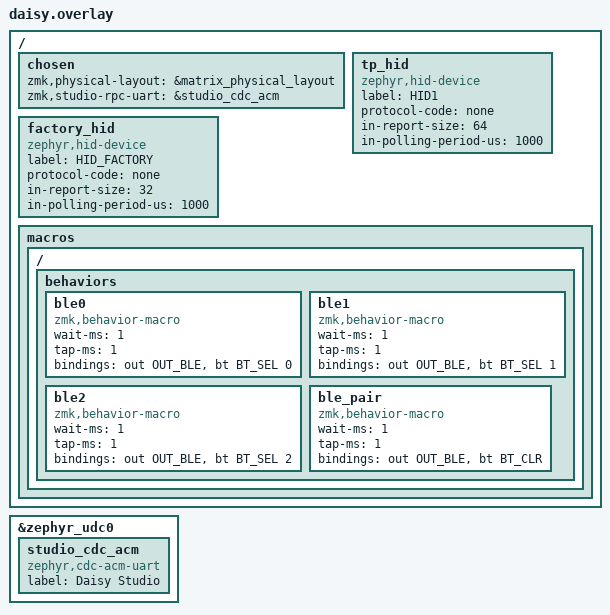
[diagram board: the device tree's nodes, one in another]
/*
 * Copyright (c) 2022 The ZMK Contributors
 *
 * SPDX-License-Identifier: MIT
 */

/* Keep every behavior node, not just the ones the keymap references, so
 * ZMK Studio can assign them at runtime (what the upstream
 * studio-rpc-usb-uart snippet does via DTS_EXTRA_CPPFLAGS; snippets don't
 * work under sysbuild). Must precede the first behaviors.dtsi include. */
#define ZMK_BEHAVIORS_KEEP_ALL

#include "daisy.dtsi"

#include <behaviors.dtsi>
#include <dt-bindings/zmk/bt.h>
#include <dt-bindings/zmk/outputs.h>

/ {
    chosen {
        zmk,physical-layout = &matrix_physical_layout;
        zmk,studio-rpc-uart = &studio_cdc_acm;
    };

    /* Second USB HID interface for the touchpad passthrough. Only
     * consumed when CONFIG_USBD_HID_SUPPORT is enabled (new USB stack);
     * ignored under the legacy stack, which routes the passthrough
     * through its own CONFIG_USB_HID_DEVICE_COUNT-based HID_1 instance. */
    tp_hid: tp_hid {
        compatible = "zephyr,hid-device";
        label = "HID1";
        protocol-code = "none";
        in-report-size = <64>;
        in-polling-period-us = <1000>;
    };

    /* Third USB HID interface carrying the vendor-defined factory-test
     * protocol (factory_hid.c). Registered only when CONFIG_DAISY_FACTORY=y. */
    factory_hid: factory_hid {
        compatible = "zephyr,hid-device";
        label = "HID_FACTORY";
        protocol-code = "none";
        in-report-size = <32>;
        in-polling-period-us = <1000>;
    };

    macros {
        ZMK_MACRO(ble0,
            wait-ms = <1>;
            tap-ms = <1>;
            bindings = <&out OUT_BLE &bt BT_SEL 0>;
        )
        ZMK_MACRO(ble1,
            wait-ms = <1>;
            tap-ms = <1>;
            bindings = <&out OUT_BLE &bt BT_SEL 1>;
        )
        ZMK_MACRO(ble2,
            wait-ms = <1>;
            tap-ms = <1>;
            bindings = <&out OUT_BLE &bt BT_SEL 2>;
        )
        ZMK_MACRO(ble_pair,
            wait-ms = <1>;
            tap-ms = <1>;
            bindings = <&out OUT_BLE &bt BT_CLR>;
        )
    };
};

/* ZMK Studio RPC over its own CDC-ACM port. */
&zephyr_udc0 {
    studio_cdc_acm: studio_cdc_acm {
        compatible = "zephyr,cdc-acm-uart";
        label = "Daisy Studio";
    };
};
